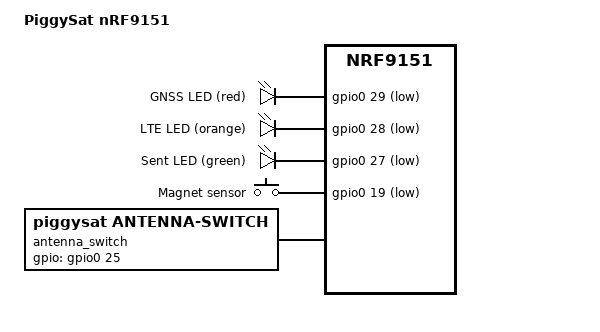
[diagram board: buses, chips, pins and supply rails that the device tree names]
/*
 * SPDX-License-Identifier: Apache-2.0
 *
 * PiggySat board (nRF9151 LACA). Pad numbers refer to the nRF9151 LGA package.
 *
 * Not available on this board: UART, I2C, SPI, external flash, MAGPIO/COEX
 * (no external LNA control). Logs go over RTT through the TC2030 SWD connector.
 */
#include <zephyr/dt-bindings/input/input-event-codes.h>

/ {
	model = "PiggySat nRF9151";
	compatible = "piggysat,piggysat-nrf9151";

	/* LEDs are tied to 3Vcc through a resistor and sunk by the GPIO. */
	leds {
		compatible = "gpio-leds";

		gnss_led: led_0 {
			gpios = <&gpio0 29 GPIO_ACTIVE_LOW>;	/* pad 48, D1, R8 4k7 */
			label = "GNSS LED (red)";
		};

		lte_led: led_1 {
			gpios = <&gpio0 28 GPIO_ACTIVE_LOW>;	/* pad 47, D2, R1 4k7 */
			label = "LTE LED (orange)";
		};

		sent_led: led_2 {
			gpios = <&gpio0 27 GPIO_ACTIVE_LOW>;	/* pad 45, D3, R4 470R */
			label = "Sent LED (green)";
		};
	};

	buttons {
		compatible = "gpio-keys";

		/* Magnet sensor on U3's push-pull output: active (low) = magnet present. */
		magnet_sensor: button_0 {
			gpios = <&gpio0 19 GPIO_ACTIVE_LOW>;	/* pad 80, U3 + S1 */
			label = "Magnet sensor";
			zephyr,code = <INPUT_KEY_0>;
		};
	};

	/* J3 header (3Vcc / SW / GND) powers the external antenna selection switch
	 * and drives its control line: low = LTE, high (active) = GNSS.
	 */
	antenna_switch: antenna-switch {
		compatible = "piggysat,antenna-switch";
		gpios = <&gpio0 25 GPIO_ACTIVE_HIGH>;	/* pad 12 */
	};

	aliases {
		led0 = &gnss_led;
		led1 = &lte_led;
		led2 = &sent_led;
		sw0 = &magnet_sensor;
		watchdog0 = &wdt0;
	};
};

&gpiote {
	status = "okay";
};

&gpio0 {
	status = "okay";
};

/* Include default memory partition configuration file */
#include <nordic/nrf91xx_partition.dtsi>

/*
 * No bootloader on this board. The default layout reserves 0x0-0x10000 for
 * MCUboot, and with devicetree partitioning (NCS v3.4+, no Partition Manager)
 * that would leave the reset vector empty. Drop the MCUboot and update slots
 * and start image slot 0 at 0x0:
 *   0x0000_0000 TF-M secure image     (256 KB)
 *   0x0004_0000 Non-secure application (256 KB)
 * TF-M storage areas stay at 0xf0000 and above.
 */
/delete-node/ &boot_partition;
/delete-node/ &slot1_partition;

&slot0_partition {
	reg = <0x00000000 0x80000>;
	ranges = <0x0 0x0 0x80000>;
};

&slot0_ns_partition {
	reg = <0x00040000 0x40000>;
};
